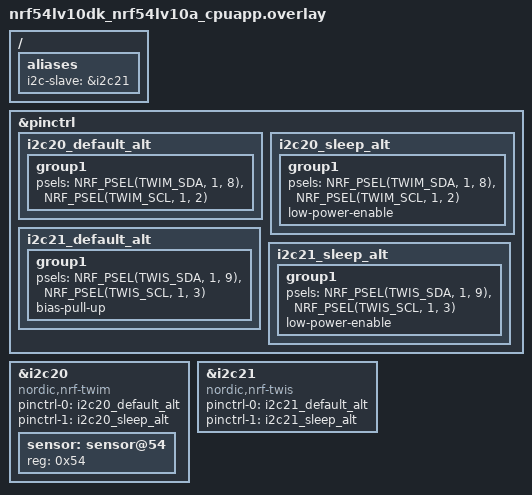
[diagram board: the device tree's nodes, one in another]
/*
 * Copyright 2026 Nordic Semiconductor ASA
 * SPDX-License-Identifier: Apache-2.0
 */

/*
 * Two loopbacks are required:
 * P1.08 - P1.09
 * P1.2 - P1.3
 */

/ {
	aliases {
		i2c-slave = &i2c21;
	};
};

&pinctrl {
	i2c20_default_alt: i2c20_default_alt {
		group1 {
			psels = <NRF_PSEL(TWIM_SDA, 1, 8)>,
				<NRF_PSEL(TWIM_SCL, 1, 2)>;
		};
	};

	i2c20_sleep_alt: i2c20_sleep_alt {
		group1 {
			psels = <NRF_PSEL(TWIM_SDA, 1, 8)>,
				<NRF_PSEL(TWIM_SCL, 1, 2)>;
			low-power-enable;
		};
	};

	i2c21_default_alt: i2c21_default_alt {
		group1 {
			psels = <NRF_PSEL(TWIS_SDA, 1, 9)>,
				<NRF_PSEL(TWIS_SCL, 1, 3)>;
			bias-pull-up;
		};
	};

	i2c21_sleep_alt: i2c21_sleep_alt {
		group1 {
			psels = <NRF_PSEL(TWIS_SDA, 1, 9)>,
				<NRF_PSEL(TWIS_SCL, 1, 3)>;
			low-power-enable;
		};
	};
};

dut_twim: &i2c20 {
	compatible = "nordic,nrf-twim";
	status = "okay";
	pinctrl-0 = <&i2c20_default_alt>;
	pinctrl-1 = <&i2c20_sleep_alt>;
	pinctrl-names = "default", "sleep";

	sensor: sensor@54 {
		reg = <0x54>;
	};
};

&i2c21 {
	compatible = "nordic,nrf-twis";
	status = "okay";
	pinctrl-0 = <&i2c21_default_alt>;
	pinctrl-1 = <&i2c21_sleep_alt>;
	pinctrl-names = "default", "sleep";
};
